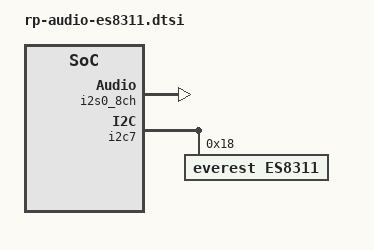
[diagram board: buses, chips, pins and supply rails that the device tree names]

/ {
    i2s0_sound: i2s0-sound {
    status = "okay";
    compatible = "simple-audio-card";
    simple-audio-card,format = "i2s";
    simple-audio-card,mclk-fs = <256>;
    simple-audio-card,name = "rockchip,es8311";
    simple-audio-card,dai-link@0 {
                        format = "i2s";
                        cpu {
                                sound-dai = <&i2s0_8ch>;
                        };
                        codec {
                                sound-dai = <&es8311>;
                        };
                };
        };
};

&i2s0_8ch {
    status = "okay";
};

&i2c7 {
        status = "okay";
    pinctrl-names = "default";
    pinctrl-0 = <&i2c7m0_xfer>;
        
        es8311: es8311@18 {
                status = "okay";
                compatible = "everest,es8311";
                reg = <0x18>;
                #sound-dai-cells = <0>;
                adc-pga-gain = <6>;     /* 18dB */
                adc-volume = <0xbf>;    /* 0dB */
                dac-volume = <0xbf>;    /* 0dB */
                aec-mode = "adc left, adc right";
                clocks = <&mclkout_i2s0>;
                clock-names = "mclk";
//                assigned-clocks = <&cru I2S0_8CH_MCLKOUT>;
 //               assigned-clock-rates = <12288000>;
                pinctrl-names = "default";
                pinctrl-0 = <&i2s0_mclk>;
        };
};

